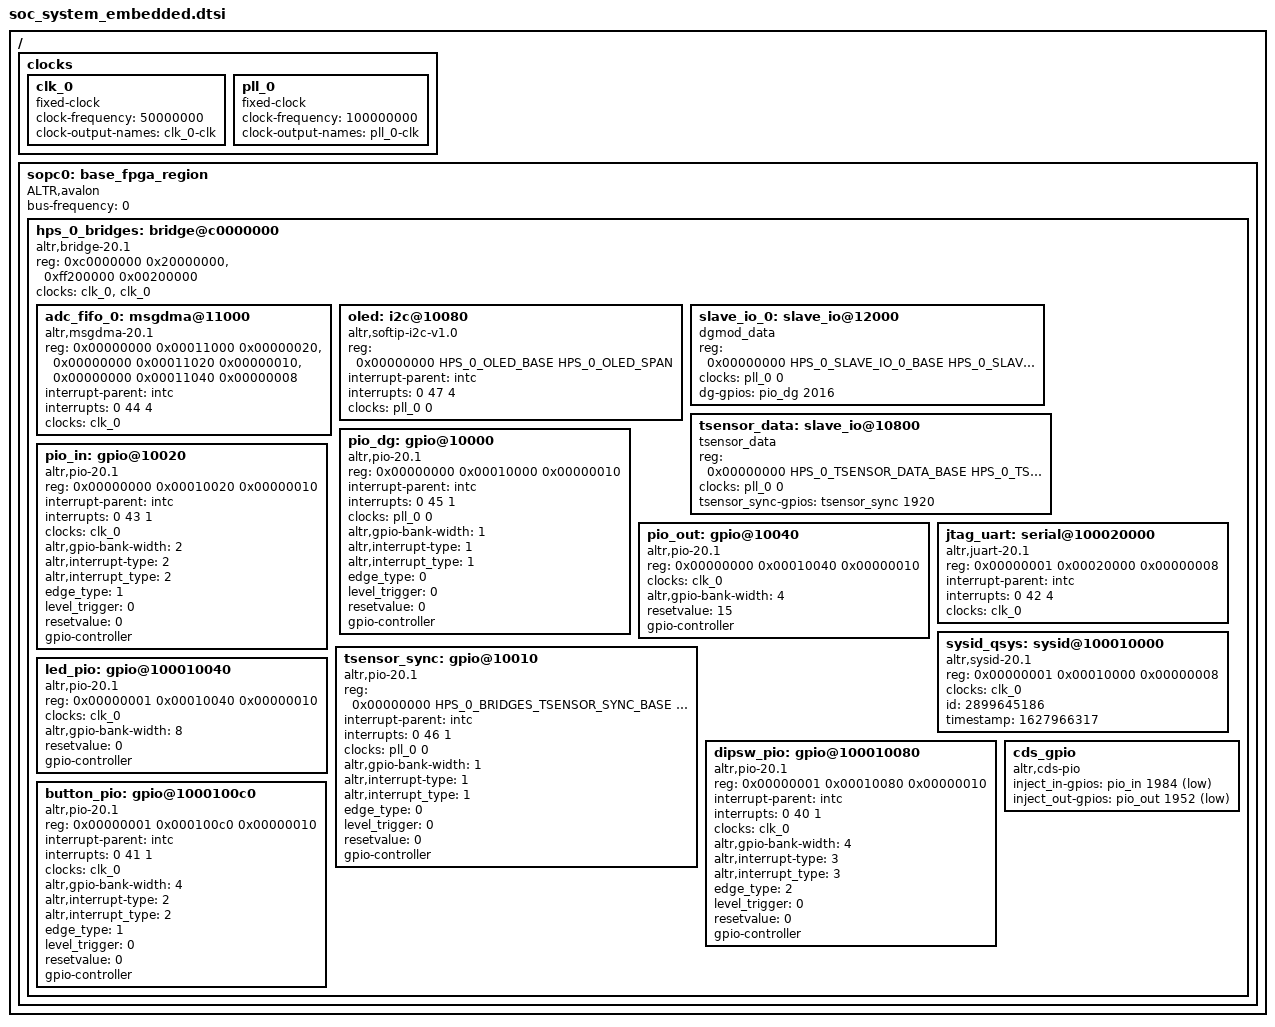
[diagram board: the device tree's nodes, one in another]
/*
 * Copyright (C) 2021-2022 MS-Chrminformatics LLC
 * Heavily modified for getting to work on de0-nano-soc.
*/

/*
 * The MIT License (MIT)
 * Copyright (c) 2017 Intel Corporation
 *
 * Permission is hereby granted, free of charge, to any person obtaining a copy
 * of this software and associated documentation files (the "Software"), to deal
 * in the Software without restriction, including without limitation the rights
 * to use, copy, modify, merge, publish, distribute, sublicense, and/or sell
 * copies of the Software, and to permit persons to whom the Software is
 * furnished to do so, subject to the following conditions:
 *
 * The above copyright notice and this permission notice shall be included in
 * all copies or substantial portions of the Software.
 *
 * THE SOFTWARE IS PROVIDED "AS IS", WITHOUT WARRANTY OF ANY KIND, EXPRESS OR
 * IMPLIED, INCLUDING BUT NOT LIMITED TO THE WARRANTIES OF MERCHANTABILITY,
 * FITNESS FOR A PARTICULAR PURPOSE AND NONINFRINGEMENT. IN NO EVENT SHALL THE
 * AUTHORS OR COPYRIGHT HOLDERS BE LIABLE FOR ANY CLAIM, DAMAGES OR OTHER
 * LIABILITY, WHETHER IN AN ACTION OF CONTRACT, TORT OR OTHERWISE, ARISING FROM,
 * OUT OF OR IN CONNECTION WITH THE SOFTWARE OR THE USE OR OTHER DEALINGS IN THE
 * SOFTWARE.
 */

#include "soc_system.h"
#include "dt-bindings/interrupt-controller/irq.h"
#include "dt-bindings/gpio/gpio.h"

/*
 * Redefine the macros from soc_system.h into shorter macros and more useful
 * values that we can use directly in the devicetree definition.
 */
#define JTAG_UART_BASE		HPS_0_ARM_A9_0_JTAG_UART_BASE
#define JTAG_UART_SPAN		HPS_0_ARM_A9_0_JTAG_UART_SPAN
#define JTAG_UART_IRQ		(HPS_0_JTAG_UART_IRQ + 72 - 32)

#define SYSID_QSYS_BASE		HPS_0_ARM_A9_0_SYSID_QSYS_BASE
#define SYSID_QSYS_SPAN		HPS_0_ARM_A9_0_SYSID_QSYS_SPAN

#define LED_PIO_BASE		HPS_0_ARM_A9_0_LED_PIO_BASE
#define LED_PIO_SPAN		HPS_0_ARM_A9_0_LED_PIO_SPAN
#define LED_PIO_WIDTH		HPS_0_ARM_A9_0_LED_PIO_DATA_WIDTH

#define DIPSW_PIO_BASE		HPS_0_ARM_A9_0_DIPSW_PIO_BASE
#define DIPSW_PIO_SPAN		HPS_0_ARM_A9_0_DIPSW_PIO_SPAN
#define DIPSW_PIO_IRQ		(HPS_0_DIPSW_PIO_IRQ + 72 - 32)
#define DIPSW_PIO_WIDTH		HPS_0_ARM_A9_0_DIPSW_PIO_DATA_WIDTH

#define BUTTON_PIO_BASE		HPS_0_ARM_A9_0_BUTTON_PIO_BASE
#define BUTTON_PIO_SPAN		HPS_0_ARM_A9_0_BUTTON_PIO_SPAN
#define BUTTON_PIO_IRQ		(HPS_0_BUTTON_PIO_IRQ + 72 - 32)
#define BUTTON_PIO_WIDTH	HPS_0_ARM_A9_0_BUTTON_PIO_DATA_WIDTH

#define ILC_BASE		HPS_0_ARM_A9_0_INTC_BASE // HPS_0_ARM_A9_0_ILC_BASE
#define ILC_SPAN		HPS_0_ARM_A9_0_INTC_SPAN // HPS_0_ARM_A9_0_ILC_SPAN

#define PIO_OUT_BASE            HPS_0_PIO_OUT_BASE
#define PIO_OUT_SPAN            HPS_0_PIO_OUT_SPAN

#define PIO_IN_BASE             HPS_0_PIO_IN_BASE
#define PIO_IN_SPAN             HPS_0_PIO_IN_SPAN
#define PIO_IN_IRQ              HPS_0_PIO_IN_IRQ

/ {
	clocks {
		clk_0: clk_0 {
			compatible = "fixed-clock";
			#clock-cells = <0>;
			clock-frequency = <50000000>;	/* 50.00 MHz */
			clock-output-names = "clk_0-clk";
		}; //end clk_0 (clk_0)

		pll_0: pll_0 {
			compatible = "fixed-clock";
			#clock-cells = <0>;
			clock-frequency = <100000000>;	/* 100.00 MHz */
			clock-output-names = "pll_0-clk";
		};
	};

    //intc: intc@fffed000 {
	//};

	sopc0: base_fpga_region {
		device_type = "soc";
		ranges;
		#address-cells = <1>;
		#size-cells = <1>;
		compatible = "ALTR,avalon", "simple-bus";
		bus-frequency = <0>;

		hps_0_bridges: bridge@c0000000 {
			compatible = "altr,bridge-20.1", "simple-bus";
			reg = <0xc0000000 0x20000000>,
				<0xff200000 0x00200000>;
			reg-names = "axi_h2f", "axi_h2f_lw";
			clocks = <&clk_0 &clk_0>;
			clock-names = "h2f_axi_clock", "h2f_lw_axi_clock";
			#address-cells = <2>;
			#size-cells = <1>;
			ranges =
			<0x00000000 0x00011000 0xc0011000 0x00000020>, // adc_fifo_0 0
			<0x00000000 0x00010080 0xc0010080 0x00000040>, // oled i2c
			<0x00000000 0x00011020 0xc0011020 0x00000010>, // adc_fifo_0 1
			<0x00000000 0x00011040 0xc0011040 0x00000008>, // adc_fifo_0 2
			<0x00000000 0x00012000 0xc0012000 0x00001000>, // slave_io_0
			<0x00000000 0x00010800 0xc0010800 0x00000800>, // tsensor_data
			<0x00000000 0x00000000 0xc0000000 0x00010000>, // onchip-memory
			<0x00000000 0x00010000 0xc0010000 0x00000010>, // pio_dg
			<0x00000000 0x00010020 0xc0010020 0x00000010>, // pio_in
			<0x00000000 0x00010040 0xc0010040 0x00000010>, // pio_out
			<0x00000000 0x00010010 0xc0010010 0x00000010>, // tsensor_sync
			<0x00000001 0x00020000 0xff220000 0x00000008>, // jtag_uart
			<0x00000001 0x00010000 0xff210000 0x00000008>, // sysid_qsys
			<0x00000001 0x00010040 0xff210040 0x00000010>, // led_pio
			<0x00000001 0x00010080 0xff210080 0x00000010>, // dipsw_pio
			<0x00000001 0x000100c0 0xff2100c0 0x00000010>; // button_pio

			adc_fifo_0: msgdma@11000 {
				compatible = "altr,msgdma-20.1", "altr,msgdma-1.0";
				reg = <0x00000000 0x00011000 0x00000020>,
					<0x00000000 0x00011020 0x00000010>,
					<0x00000000 0x00011040 0x00000008>;
				reg-names = "csr", "descriptor_slave", "response";
				interrupt-parent = <&intc>;
				interrupts = <0 44 4>;
				clocks = <&clk_0>;
			}; //end msgdma@000011000 (adc_fifo_0)

			oled: i2c@10080 {
				compatible = "altr,softip-i2c-v1.0", "altr,i2c-master-20.1", "altr,i2c-master-1.0";
				reg = <0x00000000 HPS_0_OLED_BASE HPS_0_OLED_SPAN>;
				interrupt-parent = <&intc>;
				interrupts = <0 47 4>;
				clocks = <&pll_0 0>;
			}; //end i2c@000010080 (oled)

			slave_io_0: slave_io@12000 {
				compatible = "dgmod_data"; //, "altr,avalon-mm-slave-2.0";
				reg = <0x00000000 HPS_0_SLAVE_IO_0_BASE HPS_0_SLAVE_IO_0_SPAN>; // <0x00000000 0x00012000 0x00001000>;
				clocks = <&pll_0 0>;
				dg-gpios = <&pio_dg 2016 GPIO_ACTIVE_HIGH>;
			}; //end slave_io@000012000 (slave_io_0)

			tsensor_data: slave_io@10800 {
				compatible = "tsensor_data"; //, "altr,avalon-mm-slave-2.0";
				reg = <0x00000000 HPS_0_TSENSOR_DATA_BASE HPS_0_TSENSOR_DATA_SPAN>;
				clocks = <&pll_0 0>;
				tsensor_sync-gpios = <&tsensor_sync 1920 GPIO_ACTIVE_HIGH>;
			}; //end slave_io@000010800 (tsensor_data)

			pio_dg: gpio@10000 {
				compatible = "altr,pio-20.1", "altr,pio-1.0";
				reg = <0x00000000 0x00010000 0x00000010>;
				interrupt-parent = <&intc>;
				interrupts = <0 45 1>;
				clocks = <&pll_0 0>;
				altr,gpio-bank-width = <1>;	/* embeddedsw.dts.params.altr,gpio-bank-width type NUMBER */
				altr,interrupt-type = <1>;	/* embeddedsw.dts.params.altr,interrupt-type type NUMBER */
				altr,interrupt_type = <1>;	/* embeddedsw.dts.params.altr,interrupt_type type NUMBER */
				edge_type = <0>;	        /* embeddedsw.dts.params.edge_type type NUMBER */
				level_trigger = <0>;	    /* embeddedsw.dts.params.level_trigger type NUMBER */
				resetvalue = <0>;	        /* embeddedsw.dts.params.resetvalue type NUMBER */
				#gpio-cells = <2>;
				gpio-controller;
			}; //end gpio@000010000 (pio_dg)

			pio_in: gpio@10020 {
				compatible = "altr,pio-20.1", "altr,pio-1.0";
				reg = <0x00000000 0x00010020 0x00000010>;
				interrupt-parent = <&intc>;
				interrupts = <0 43 1>;
				clocks = <&clk_0>;
				altr,gpio-bank-width = <2>;	/* embeddedsw.dts.params.altr,gpio-bank-width type NUMBER */
				altr,interrupt-type = <2>;	/* embeddedsw.dts.params.altr,interrupt-type type NUMBER */
				altr,interrupt_type = <2>;	/* embeddedsw.dts.params.altr,interrupt_type type NUMBER */
				edge_type = <1>;	        /* embeddedsw.dts.params.edge_type type NUMBER */
				level_trigger = <0>;	    /* embeddedsw.dts.params.level_trigger type NUMBER */
				resetvalue = <0>;	        /* embeddedsw.dts.params.resetvalue type NUMBER */
				#gpio-cells = <2>;
				gpio-controller;
			}; //end gpio@000010020 (pio_in)

			pio_out: gpio@10040 {
				compatible = "altr,pio-20.1", "altr,pio-1.0";
				reg = <0x00000000 0x00010040 0x00000010>;
				clocks = <&clk_0>;
				altr,gpio-bank-width = <4>;	/* embeddedsw.dts.params.altr,gpio-bank-width type NUMBER */
				resetvalue = <15>;	        /* embeddedsw.dts.params.resetvalue type NUMBER */
				#gpio-cells = <2>;
				gpio-controller;
			}; //end gpio@000010040 (pio_out)

			tsensor_sync: gpio@10010 {
				compatible = "altr,pio-20.1", "altr,pio-1.0";
				reg = <0x00000000 HPS_0_BRIDGES_TSENSOR_SYNC_BASE HPS_0_BRIDGES_TSENSOR_SYNC_SPAN>;
				interrupt-parent = <&intc>;
				interrupts = <0 46 1>;
				clocks = <&pll_0 0>;
				altr,gpio-bank-width = <1>;	/* embeddedsw.dts.params.altr,gpio-bank-width type NUMBER */
				altr,interrupt-type = <1>;	/* embeddedsw.dts.params.altr,interrupt-type type NUMBER */
				altr,interrupt_type = <1>;	/* embeddedsw.dts.params.altr,interrupt_type type NUMBER */
				edge_type = <0>;	/* embeddedsw.dts.params.edge_type type NUMBER */
				level_trigger = <0>;	/* embeddedsw.dts.params.level_trigger type NUMBER */
				resetvalue = <0>;	/* embeddedsw.dts.params.resetvalue type NUMBER */
				#gpio-cells = <2>;
				gpio-controller;
			}; //end gpio@000010010 (tsensor_sync)

			jtag_uart: serial@100020000 {
				compatible = "altr,juart-20.1", "altr,juart-1.0";
				reg = <0x00000001 0x00020000 0x00000008>;
				interrupt-parent = <&intc>;
				interrupts = <0 42 4>;
				clocks = <&clk_0>;
			}; //end serial@100020000 (jtag_uart)

			sysid_qsys: sysid@100010000 {
				compatible = "altr,sysid-20.1", "altr,sysid-1.0";
				reg = <0x00000001 0x00010000 0x00000008>;
				clocks = <&clk_0>;
				id = <2899645186>;	/* embeddedsw.dts.params.id type NUMBER */
				timestamp = <1627966317>;	/* embeddedsw.dts.params.timestamp type NUMBER */
			}; //end sysid@100010000 (sysid_qsys)

			led_pio: gpio@100010040 {
				compatible = "altr,pio-20.1", "altr,pio-1.0";
				reg = <0x00000001 0x00010040 0x00000010>;
				clocks = <&clk_0>;
				altr,gpio-bank-width = <8>;	/* embeddedsw.dts.params.altr,gpio-bank-width type NUMBER */
				resetvalue = <0>;	/* embeddedsw.dts.params.resetvalue type NUMBER */
				#gpio-cells = <2>;
				gpio-controller;
			};

			dipsw_pio: gpio@100010080 {
				compatible = "altr,pio-20.1", "altr,pio-1.0";
				reg = <0x00000001 0x00010080 0x00000010>;
				interrupt-parent = <&intc>;
				interrupts = <0 40 1>;
				clocks = <&clk_0>;
				altr,gpio-bank-width = <4>;	/* embeddedsw.dts.params.altr,gpio-bank-width type NUMBER */
				altr,interrupt-type = <3>;	/* embeddedsw.dts.params.altr,interrupt-type type NUMBER */
				altr,interrupt_type = <3>;	/* embeddedsw.dts.params.altr,interrupt_type type NUMBER */
				edge_type = <2>;	/* embeddedsw.dts.params.edge_type type NUMBER */
				level_trigger = <0>;	/* embeddedsw.dts.params.level_trigger type NUMBER */
				resetvalue = <0>;	/* embeddedsw.dts.params.resetvalue type NUMBER */
				#gpio-cells = <2>;
				gpio-controller;
			};

			button_pio: gpio@1000100c0 {
				compatible = "altr,pio-20.1", "altr,pio-1.0";
				reg = <0x00000001 0x000100c0 0x00000010>;
				interrupt-parent = <&intc>;
				interrupts = <0 41 1>;
				clocks = <&clk_0>;
				altr,gpio-bank-width = <4>;	/* embeddedsw.dts.params.altr,gpio-bank-width type NUMBER */
				altr,interrupt-type = <2>;	/* embeddedsw.dts.params.altr,interrupt-type type NUMBER */
				altr,interrupt_type = <2>;	/* embeddedsw.dts.params.altr,interrupt_type type NUMBER */
				edge_type = <1>;	/* embeddedsw.dts.params.edge_type type NUMBER */
				level_trigger = <0>;	/* embeddedsw.dts.params.level_trigger type NUMBER */
				resetvalue = <0>;	/* embeddedsw.dts.params.resetvalue type NUMBER */
				#gpio-cells = <2>;
				gpio-controller;
			};

			cds_gpio {
				compatible  = "altr,cds-pio"; // consumer
				inject_in-gpios = <&pio_in 1984 GPIO_ACTIVE_LOW>;
				inject_out-gpios = <&pio_out 1952 GPIO_ACTIVE_LOW>;
			};

		}; //end bridge@c0000000 (hps_0_bridges)
	}; // sopc@0
}; // /

/*
base_fpga_region/c0000000.bridge/ff2100c0.gpio/gpio/gpiochip1824 // button_pio
base_fpga_region/c0000000.bridge/ff210080.gpio/gpio/gpiochip1856 // dipsw_pio
base_fpga_region/c0000000.bridge/ff210040.gpio/gpio/gpiochip1888 // led_pio

base_fpga_region/c0000000.bridge/c0010010.gpio/gpio/gpiochip1920 // tsensor_sync
base_fpga_region/c0000000.bridge/c0010040.gpio/gpio/gpiochip1952 // pio_out
base_fpga_region/c0000000.bridge/c0010020.gpio/gpio/gpiochip1984 // pio_in
base_fpga_region/c0000000.bridge/c0010000.gpio/gpio/gpiochip2016 // pio_dg
*/
